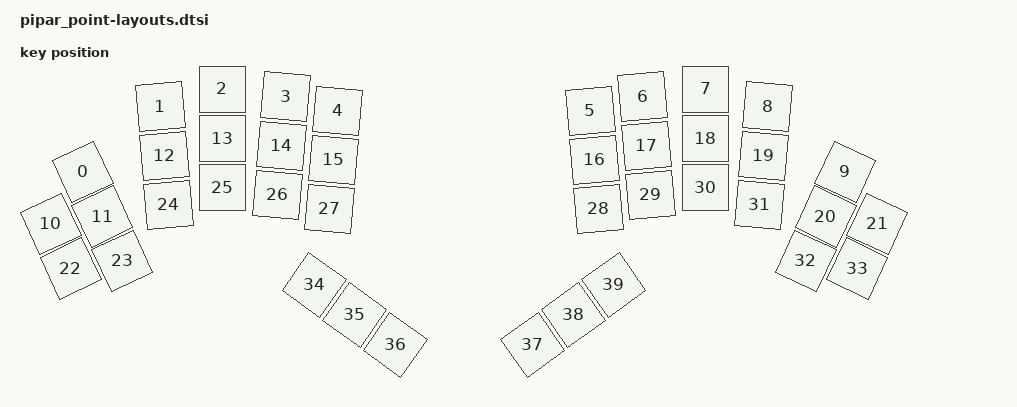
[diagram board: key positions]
#include <physical_layouts.dtsi>

/ {
    physical_layout0: physical_layout_0 {
        compatible = "zmk,physical-layout";
        display-name = "pipar_point-layout";

        keys  //                     w   h    x    y     rot    rx    ry
            = <&key_physical_attrs 100 100   61  166 (-2500)   111   216>
            , <&key_physical_attrs 100 100  216   35  (-500)   266    85>
            , <&key_physical_attrs 100 100  340    0       0     0     0>
            , <&key_physical_attrs 100 100  467   15     500   517    65>
            , <&key_physical_attrs 100 100  571   44     500   621    94>
            , <&key_physical_attrs 100 100 1076   44  (-500)  1126    94>
            , <&key_physical_attrs 100 100 1181   15  (-500)  1231    65>
            , <&key_physical_attrs 100 100 1307    0       0     0     0>
            , <&key_physical_attrs 100 100 1431   35     500  1481    85>
            , <&key_physical_attrs 100 100 1586  166    2500  1636   216>
            , <&key_physical_attrs 100 100    0  225 (-2500)   150   305>
            , <&key_physical_attrs 100 100  100  255 (-2500)   150   305>
            , <&key_physical_attrs 100 100  224  134  (-500)   274   184>
            , <&key_physical_attrs 100 100  340   99       0     0     0>
            , <&key_physical_attrs 100 100  458  114     500   508   164>
            , <&key_physical_attrs 100 100  563  142     500   613   192>
            , <&key_physical_attrs 100 100 1084  142  (-500)  1134   192>
            , <&key_physical_attrs 100 100 1189  114  (-500)  1239   164>
            , <&key_physical_attrs 100 100 1307   99       0     0     0>
            , <&key_physical_attrs 100 100 1423  134     500  1473   184>
            , <&key_physical_attrs 100 100 1547  255    2500  1597   305>
            , <&key_physical_attrs 100 100 1647  225    2500  1597   305>
            , <&key_physical_attrs 100 100   40  314 (-2500)   190   394>
            , <&key_physical_attrs 100 100  140  344 (-2500)   190   394>
            , <&key_physical_attrs 100 100  232  232  (-500)   282   282>
            , <&key_physical_attrs 100 100  340  197       0     0     0>
            , <&key_physical_attrs 100 100  450  212     500   500   262>
            , <&key_physical_attrs 100 100  555  240     500   605   290>
            , <&key_physical_attrs 100 100 1092  240  (-500)  1142   290>
            , <&key_physical_attrs 100 100 1197  212  (-500)  1247   262>
            , <&key_physical_attrs 100 100 1307  197       0     0     0>
            , <&key_physical_attrs 100 100 1415  232     500  1465   282>
            , <&key_physical_attrs 100 100 1507  344    2500  1557   394>
            , <&key_physical_attrs 100 100 1607  314    2500  1557   394>
            , <&key_physical_attrs 100 100  524  392    3500   574   442>
            , <&key_physical_attrs 100 100  605  452    3500   655   502>
            , <&key_physical_attrs 100 100  686  512    3500   736   562>
            , <&key_physical_attrs 100 100  961  512 (-3500)  1011   562>
            , <&key_physical_attrs 100 100 1042  452 (-3500)  1092   502>
            , <&key_physical_attrs 100 100 1123  392 (-3500)  1173   442>
            ;
    };
};
